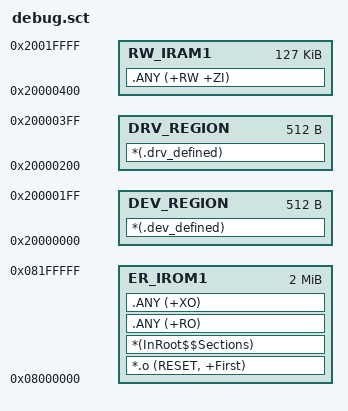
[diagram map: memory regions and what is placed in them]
; armfly-v7 scatter file for STM32H743XIH6

LR_IROM1 0x08000000 0x00200000  {
  ER_IROM1 0x08000000 0x00200000  {
   *.o (RESET, +First)
   *(InRoot$$Sections)
   .ANY (+RO)
   .ANY (+XO)
  }

  DEV_REGION 0x20000000 0x00000200  {
   *(.dev_defined)
  }

  DRV_REGION 0x20000200 0x00000200  {
   *(.drv_defined)
  }

  RW_IRAM1 0x20000400 0x0001FC00  {
   .ANY (+RW +ZI)
  }
}
